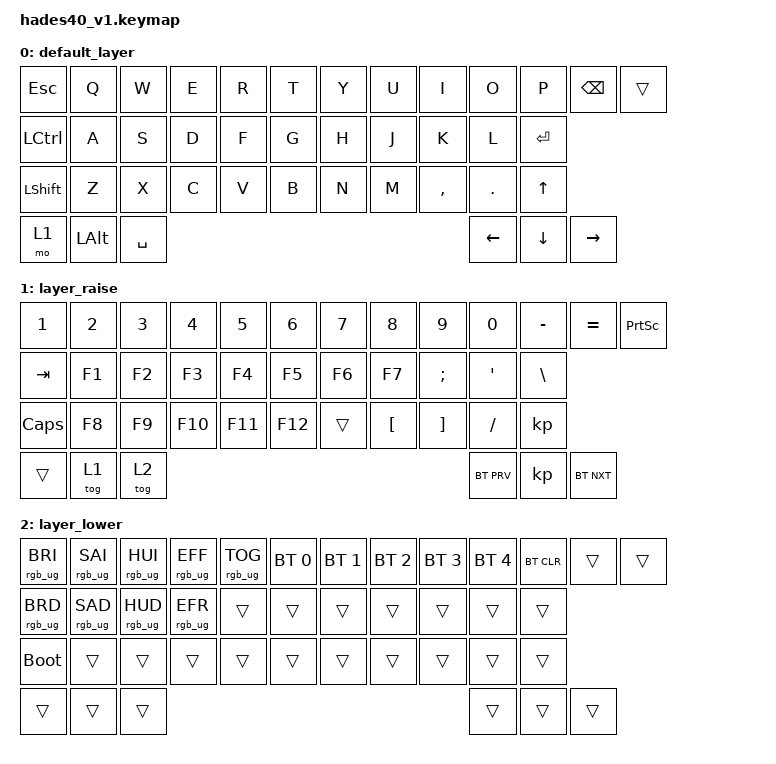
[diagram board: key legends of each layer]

/*
 * Copyright (c) 2020 The ZMK Contributors
 *
 * SPDX-License-Identifier: MIT
 */


/* THIS FILE WAS GENERATED!
 *
 * This file was generated automatically. You may or may not want to
 * edit it directly.
 */

#include <behaviors.dtsi>
#include <dt-bindings/zmk/keys.h>
#include <dt-bindings/zmk/bt.h>
#include <dt-bindings/zmk/rgb.h>

/ {
    keymap {
        compatible = "zmk,keymap";


        default_layer {
            bindings = <
   &kp ESC     &kp Q   &kp W   &kp E   &kp R      &kp T            &kp Y   &kp U      &kp I       &kp O      &kp P   &kp BSPC  &trans
 &kp LCTRL     &kp A   &kp S   &kp D   &kp F      &kp G            &kp H   &kp J      &kp K       &kp L  &kp ENTER
 &kp LSHFT     &kp Z   &kp X   &kp C   &kp V      &kp B            &kp N   &kp M  &kp COMMA  &kp PERIOD     &kp UP
     &mo 1  &kp LALT                          &kp SPACE                            &kp LEFT               &kp DOWN  &kp RIGHT
            >;
        };

        layer_raise {
            bindings = <
   &kp N1  &kp N2  &kp N3   &kp N4   &kp N5   &kp N6            &kp N7            &kp N8             &kp N9            &kp N0  &kp MINUS   &kp EQUAL  &kp PSCRN
  &kp TAB  &kp F1  &kp F2   &kp F3   &kp F4   &kp F5            &kp F6            &kp F7      &kp SEMICOLON  &kp SINGLE_QUOTE   &kp BSLH
 &kp CAPS  &kp F8  &kp F9  &kp F10  &kp F11  &kp F12            &trans  &kp LEFT_BRACKET  &kp RIGHT_BRACKET         &kp SLASH        &kp
   &trans  &tog 1                             &tog 2                                             &bt BT_PRV                          &kp  &bt BT_NXT
            >;
        };

        layer_lower {
            bindings = <
 &rgb_ug RGB_BRI  &rgb_ug RGB_SAI  &rgb_ug RGB_HUI  &rgb_ug RGB_EFF  &rgb_ug RGB_TOG  &bt BT_SEL 0            &bt BT_SEL 1  &bt BT_SEL 2  &bt BT_SEL 3  &bt BT_SEL 4  &bt BT_CLR  &trans  &trans
 &rgb_ug RGB_BRD  &rgb_ug RGB_SAD  &rgb_ug RGB_HUD  &rgb_ug RGB_EFR           &trans        &trans                  &trans        &trans        &trans        &trans      &trans
     &bootloader           &trans           &trans           &trans           &trans        &trans                  &trans        &trans        &trans        &trans      &trans
          &trans           &trans                                                           &trans                                              &trans                    &trans  &trans
            >;
        };

    };
};
